VERSION ""

NS_ :

BS_:

BU_: XXX

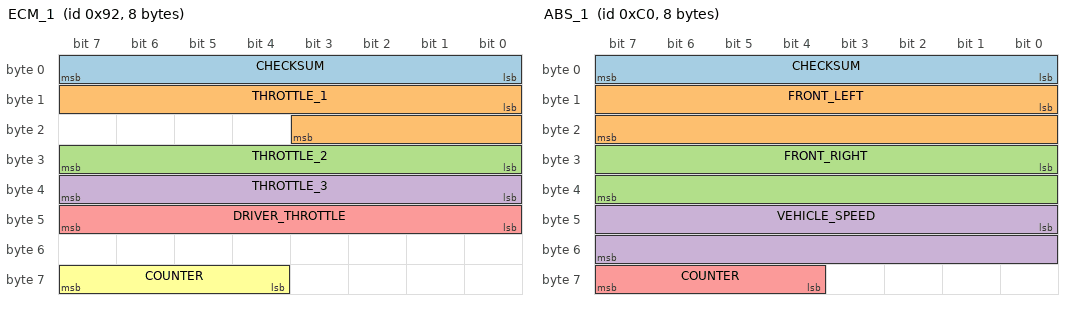
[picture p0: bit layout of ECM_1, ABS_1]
BO_ 146 ECM_1: 8 XXX
 SG_ CHECKSUM : 0|8@1+ (1,0) [0|255] "" XXX
 SG_ THROTTLE_1 : 8|12@1+ (1,0) [0|255] "" XXX
 SG_ THROTTLE_2 : 24|8@1+ (1,0) [0|255] "" XXX
 SG_ THROTTLE_3 : 32|8@1+ (1,0) [0|255] "" XXX
 SG_ DRIVER_THROTTLE : 40|8@1+ (1,0) [0|255] "" XXX
 SG_ COUNTER : 60|4@1+ (1,0) [0|15] "" XXX

BO_ 192 ABS_1: 8 XXX
 SG_ CHECKSUM : 0|8@1+ (1,0) [0|15] "" XXX
 SG_ FRONT_LEFT : 8|16@1+ (0.01,0) [0|65535] "km/h" XXX
 SG_ FRONT_RIGHT : 24|16@1+ (0.01,0) [0|65535] "km/h" XXX
 SG_ VEHICLE_SPEED : 40|16@1+ (0.01,0) [0|65535] "km/h" XXX
 SG_ COUNTER : 60|4@1+ (1,0) [0|15] "" XXX

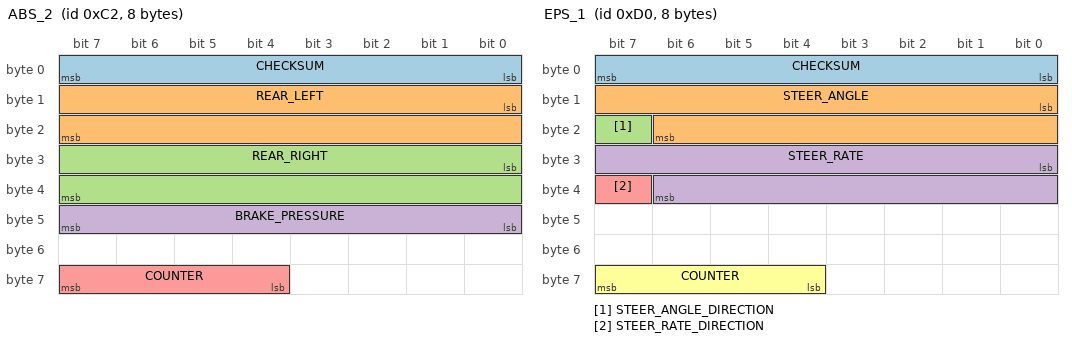
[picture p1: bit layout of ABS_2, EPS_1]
BO_ 194 ABS_2: 8 XXX
 SG_ CHECKSUM : 0|8@1+ (1,0) [0|15] "" XXX
 SG_ REAR_LEFT : 8|16@1+ (0.01,0) [0|65535] "km/h" XXX
 SG_ REAR_RIGHT : 24|16@1+ (0.01,0) [0|65535] "km/h" XXX
 SG_ BRAKE_PRESSURE : 40|8@1+ (1,0) [0|255] "" XXX
 SG_ COUNTER : 60|4@1+ (1,0) [0|15] "" XXX

BO_ 208 EPS_1: 8 XXX
 SG_ CHECKSUM : 0|8@1+ (1,0) [0|15] "" XXX
 SG_ STEER_ANGLE : 8|15@1+ (0.0225,0) [0|65535] "" XXX
 SG_ STEER_ANGLE_DIRECTION : 23|1@1+ (1,0) [0|1] "direction" XXX
 SG_ STEER_RATE : 24|15@1+ (0.0225,0) [0|65535] "" XXX
 SG_ STEER_RATE_DIRECTION : 39|1@1+ (1,0) [0|1] "direction" XXX
 SG_ COUNTER : 60|4@1+ (1,0) [0|15] "" XXX

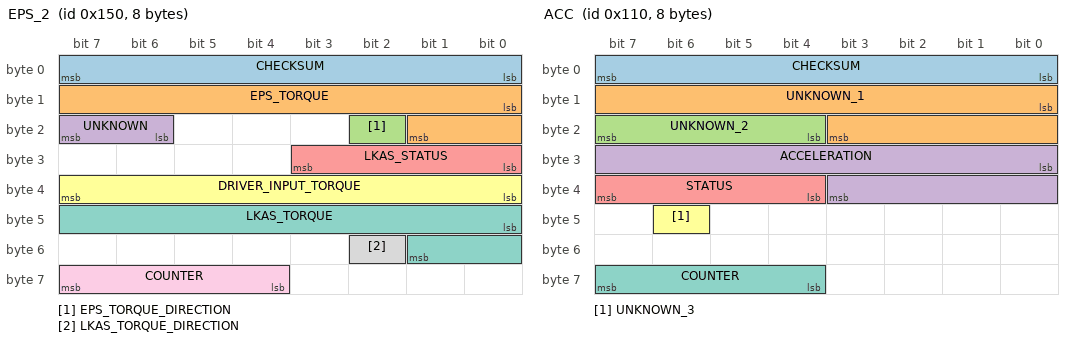
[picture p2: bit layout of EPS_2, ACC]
BO_ 336 EPS_2: 8 XXX
 SG_ CHECKSUM : 0|8@1+ (1,0) [0|255] "" XXX
 SG_ EPS_TORQUE : 8|10@1- (1,0) [0|255] "" XXX
 SG_ EPS_TORQUE_DIRECTION : 18|1@1+ (1,0) [0|1] "direction" XXX
 SG_ UNKNOWN : 22|2@1+ (1,0) [0|3] "" XXX
 SG_ LKAS_STATUS : 24|4@1+ (1,0) [0|15] "" XXX
 SG_ DRIVER_INPUT_TORQUE : 32|8@1+ (1,0) [0|255] "" XXX
 SG_ LKAS_TORQUE : 40|10@1+ (1,0) [0|1023] "" XXX
 SG_ LKAS_TORQUE_DIRECTION : 50|1@1+ (1,0) [0|1] "" XXX
 SG_ COUNTER : 60|4@1+ (1,0) [0|15] "" XXX

BO_ 272 ACC: 8 XXX
 SG_ CHECKSUM : 0|8@1+ (1,0) [0|255] "" XXX
 SG_ UNKNOWN_1 : 8|12@1+ (1,0) [0|4095] "" XXX
 SG_ UNKNOWN_2 : 20|4@1+ (1,0) [0|15] "" XXX
 SG_ ACCELERATION : 24|12@1+ (1,-300) [0|255] "" XXX
 SG_ STATUS : 36|4@1+ (1,0) [0|31] "x" XXX
 SG_ UNKNOWN_3 : 46|1@1+ (1,0) [0|1] "" XXX
 SG_ COUNTER : 60|4@1+ (1,0) [0|15] "" XXX

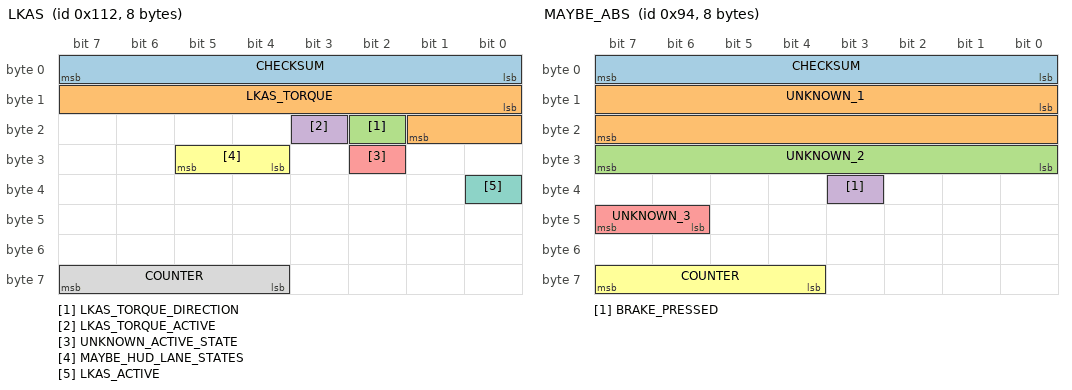
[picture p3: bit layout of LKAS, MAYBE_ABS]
BO_ 274 LKAS: 8 XXX
 SG_ CHECKSUM : 0|8@1+ (1,0) [0|255] "" XXX
 SG_ LKAS_TORQUE : 8|10@1+ (1,0) [0|2047] "x" XXX
 SG_ LKAS_TORQUE_DIRECTION : 18|1@1+ (1,0) [0|1] "" XXX
 SG_ LKAS_TORQUE_ACTIVE : 19|1@1+ (1,0) [0|1] "" XXX
 SG_ UNKNOWN_ACTIVE_STATE : 26|1@1+ (1,0) [0|1] "" XXX
 SG_ MAYBE_HUD_LANE_STATES : 28|2@1+ (1,0) [0|3] "" XXX
 SG_ LKAS_ACTIVE : 32|1@1+ (1,0) [0|255] "" XXX
 SG_ COUNTER : 60|4@1+ (1,0) [0|15] "" XXX

BO_ 148 MAYBE_ABS: 8 XXX
 SG_ CHECKSUM : 0|8@1+ (1,0) [0|255] "" XXX
 SG_ UNKNOWN_1 : 8|16@1+ (1,0) [0|15] "x" XXX
 SG_ UNKNOWN_2 : 24|8@1+ (1,0) [0|255] "" XXX
 SG_ BRAKE_PRESSED : 35|1@1+ (1,0) [0|1] "x" XXX
 SG_ UNKNOWN_3 : 46|2@1+ (1,0) [0|3] "" XXX
 SG_ COUNTER : 60|4@1+ (1,0) [0|15] "" XXX

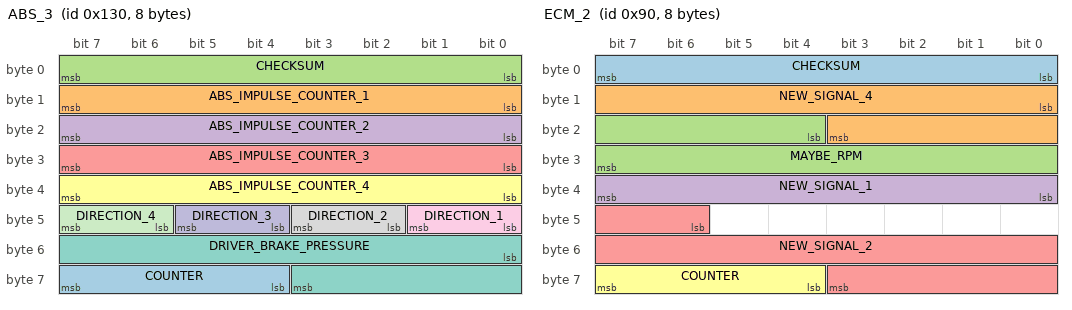
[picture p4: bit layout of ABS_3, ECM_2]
BO_ 304 ABS_3: 8 XXX
 SG_ COUNTER : 60|4@1+ (1,0) [0|15] "" XXX
 SG_ ABS_IMPULSE_COUNTER_1 : 8|8@1+ (1,0) [0|255] "" XXX
 SG_ CHECKSUM : 0|8@1+ (1,0) [0|15] "" XXX
 SG_ ABS_IMPULSE_COUNTER_2 : 16|8@1+ (1,0) [0|255] "" XXX
 SG_ ABS_IMPULSE_COUNTER_3 : 24|8@1+ (1,0) [0|255] "" XXX
 SG_ ABS_IMPULSE_COUNTER_4 : 32|8@1+ (1,0) [0|255] "" XXX
 SG_ DRIVER_BRAKE_PRESSURE : 48|12@1+ (1,0) [0|65535] "" XXX
 SG_ DIRECTION_2 : 42|2@1+ (1,0) [0|3] "" XXX
 SG_ DIRECTION_1 : 40|2@1+ (1,0) [0|3] "" XXX
 SG_ DIRECTION_3 : 44|2@1+ (1,0) [0|3] "" XXX
 SG_ DIRECTION_4 : 46|2@1+ (1,0) [0|3] "" XXX

BO_ 308 NEW_MSG_2: 8 XXX

BO_ 144 ECM_2: 8 XXX
 SG_ CHECKSUM : 0|8@1+ (1,0) [0|255] "" XXX
 SG_ NEW_SIGNAL_4 : 8|12@1+ (1,0) [0|255] "" XXX
 SG_ MAYBE_RPM : 20|12@1+ (1,0) [0|15] "x" XXX
 SG_ NEW_SIGNAL_1 : 32|8@1+ (1,0) [0|255] "" XXX
 SG_ NEW_SIGNAL_2 : 46|14@1+ (1,0) [0|4095] "" XXX
 SG_ COUNTER : 60|4@1+ (1,0) [0|15] "" XXX

BO_ 422 MAYBE_ACC_BUTTONS: 8 XXX
 SG_ NEW_SIGNAL_1 : 18|1@0+ (1,0) [0|1] "x" XXX

BO_ 306 NEW_MSG_1: 8 XXX
 SG_ COUNTER : 63|4@0+ (1,0) [0|15] "" XXX
 SG_ CHECKSUM : 7|8@0+ (1,0) [0|255] "" XXX

BO_ 586 DOOR_LF: 8 XXX
 SG_ OPEN : 2|1@1+ (1,0) [0|1] "" XXX

BO_ 588 DOOR_RF: 8 XXX
 SG_ OPEN : 2|1@1+ (1,0) [0|1] "" XXX

BO_ 590 DOOR_RL: 8 XXX
 SG_ OPEN : 2|1@1+ (1,0) [0|1] "" XXX

BO_ 591 DOOR_RR: 8 XXX
 SG_ OPEN : 2|1@1+ (1,0) [0|1] "" XXX

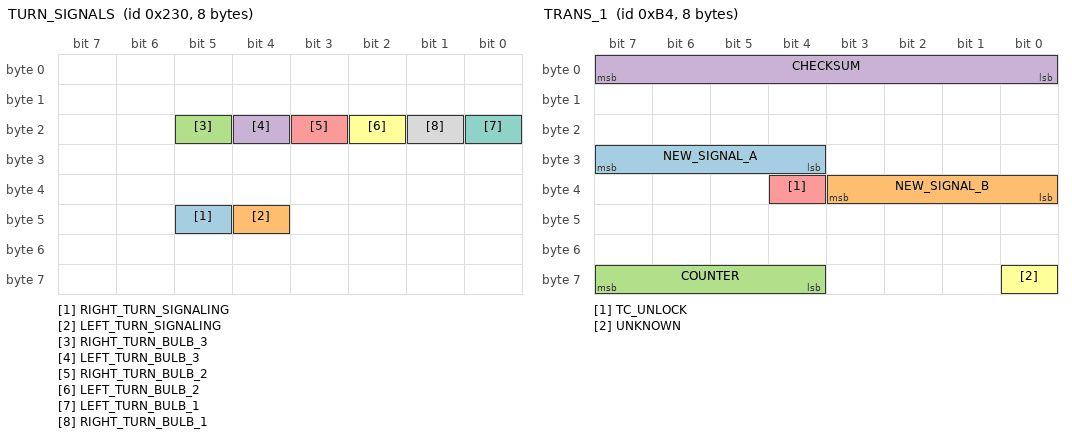
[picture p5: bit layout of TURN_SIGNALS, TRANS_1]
BO_ 560 TURN_SIGNALS: 8 XXX
 SG_ RIGHT_TURN_SIGNALING : 45|1@1+ (1,0) [0|1] "" XXX
 SG_ LEFT_TURN_SIGNALING : 44|1@1+ (1,0) [0|1] "" XXX
 SG_ RIGHT_TURN_BULB_3 : 21|1@1+ (1,0) [0|1] "" XXX
 SG_ LEFT_TURN_BULB_3 : 20|1@1+ (1,0) [0|1] "" XXX
 SG_ RIGHT_TURN_BULB_2 : 19|1@1+ (1,0) [0|1] "" XXX
 SG_ LEFT_TURN_BULB_2 : 18|1@1+ (1,0) [0|1] "" XXX
 SG_ LEFT_TURN_BULB_1 : 16|1@1+ (1,0) [0|1] "" XXX
 SG_ RIGHT_TURN_BULB_1 : 17|1@1+ (1,0) [0|1] "" XXX

BO_ 180 TRANS_1: 8 XXX
 SG_ NEW_SIGNAL_A : 28|4@1+ (1,0) [0|255] "" XXX
 SG_ NEW_SIGNAL_B : 32|4@1+ (1,0) [0|255] "" XXX
 SG_ COUNTER : 63|4@0+ (1,0) [0|15] "" XXX
 SG_ CHECKSUM : 7|8@0+ (1,0) [0|255] "" XXX
 SG_ TC_UNLOCK : 36|1@1+ (1,0) [0|1] "" XXX
 SG_ UNKNOWN : 56|1@1+ (1,0) [0|1] "" XXX

CM_ SG_ 274 UNKNOWN_ACTIVE_STATE "Triggers changes from 8 to 9 in EPS_2.LKAS_STATUS";
CM_ SG_ 560 RIGHT_TURN_SIGNALING "Includes 2.5 second convenience lane change interval";
CM_ SG_ 560 LEFT_TURN_SIGNALING "Includes 2.5 second convenience lane change interval";
CM_ SG_ 180 TC_UNLOCK "AT torque converter unlocked (guessed)";
CM_ SG_ 180 UNKNOWN "May be a neutral or parking-pawl indicator";
VAL_ 336 LKAS_STATUS 1 "INITIALIZING" 5 "READY" 8 "ACTIVE_1" 9 "ACTIVE_2" 13 "FAULT" ;
VAL_ 304 DIRECTION_2 0 "STANDSTILL" 1 "FORWARD" 2 "REVERSE" ;
VAL_ 304 DIRECTION_1 0 "STANDSTILL" 1 "FORWARD" 2 "REVERSE" ;
VAL_ 304 DIRECTION_3 0 "STANDSTILL" 1 "FORWARD" 2 "REVERSE" ;
VAL_ 304 DIRECTION_4 0 "STANDSTILL" 1 "FORWARD" 2 "REVERSE" ;
VAL_ 586 OPEN 0 "CLOSED" 1 "OPEN" ;
VAL_ 588 OPEN 0 "CLOSED" 1 "OPEN" ;
VAL_ 590 OPEN 0 "CLOSED" 1 "OPEN" ;
VAL_ 591 OPEN 0 "CLOSED" 1 "OPEN" ;
